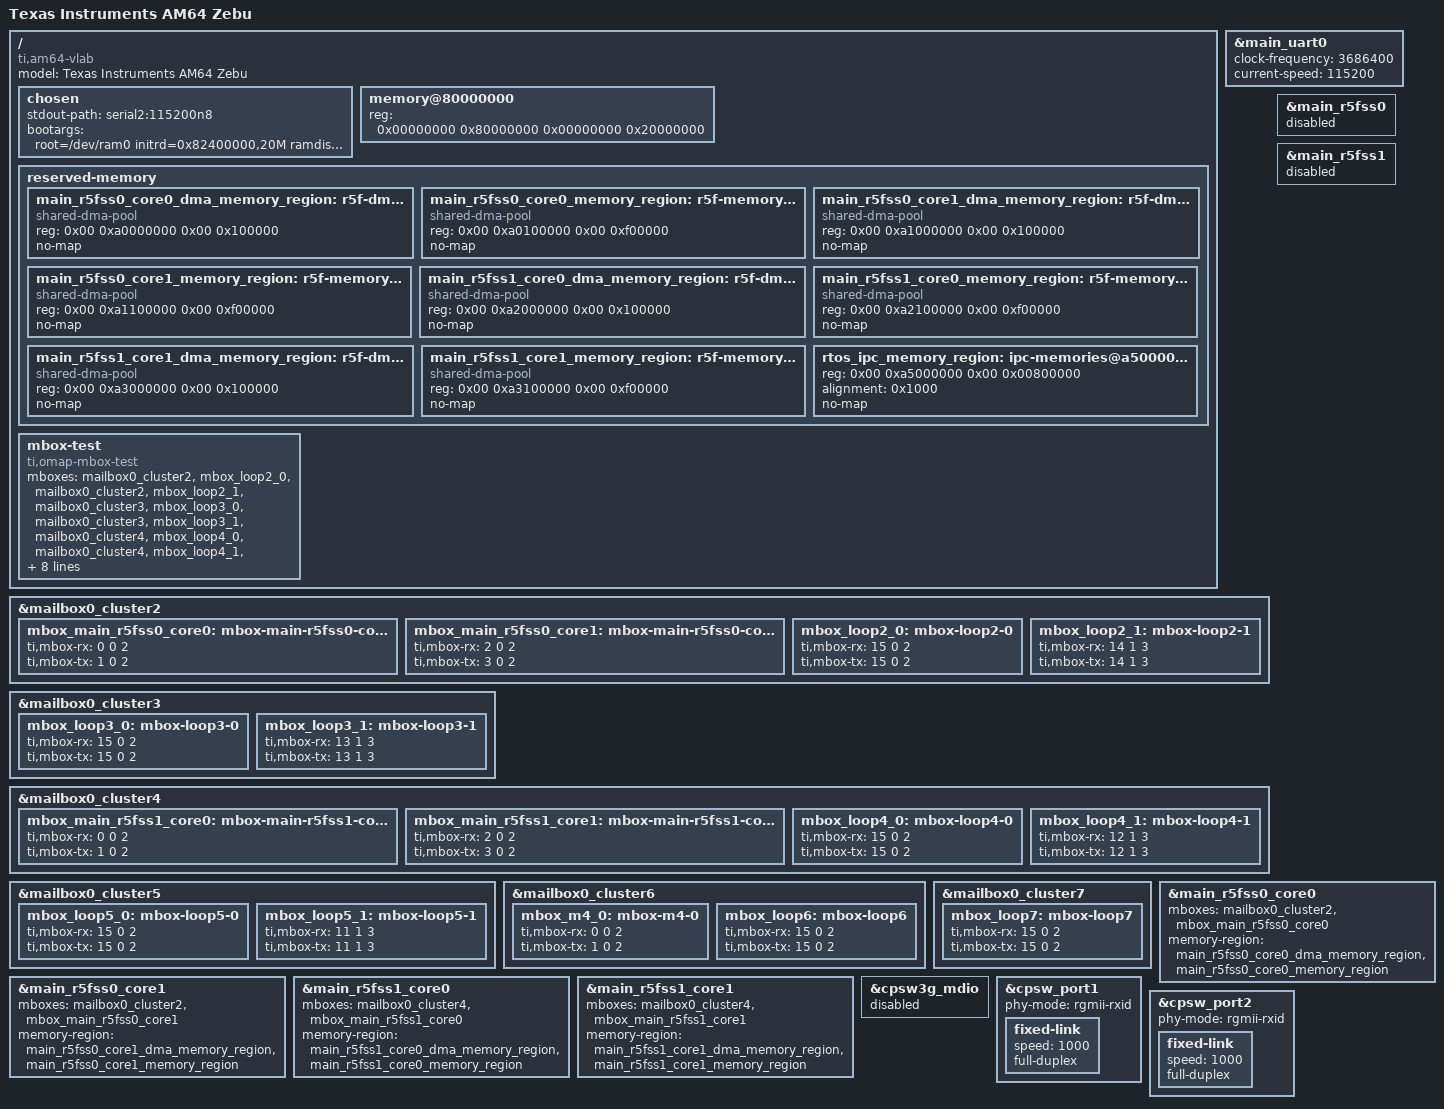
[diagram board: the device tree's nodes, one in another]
// SPDX-License-Identifier: GPL-2.0
/*
 * Copyright (C) 2020 Texas Instruments Incorporated - http://www.ti.com/
 */

/dts-v1/;

#include "k3-am642.dtsi"

/ {
	compatible =  "ti,am64-vlab", "ti,am64";
	model = "Texas Instruments AM64 Zebu";

	chosen {
		stdout-path = "serial2:115200n8";
		bootargs = "root=/dev/ram0 initrd=0x82400000,20M ramdisk_size=20480 init=/bin/sh console=ttyS2,115200n8 earlycon=ns16550a,mmio32,0x02800000";
	};

	memory@80000000 {
		device_type = "memory";
		/* 512MB RAM */
		reg = <0x00000000 0x80000000 0x00000000 0x20000000>;

	};

	reserved-memory {
		#address-cells = <2>;
		#size-cells = <2>;
		ranges;

		main_r5fss0_core0_dma_memory_region: r5f-dma-memory@a0000000 {
			compatible = "shared-dma-pool";
			reg = <0x00 0xa0000000 0x00 0x100000>;
			no-map;
		};

		main_r5fss0_core0_memory_region: r5f-memory@a0100000 {
			compatible = "shared-dma-pool";
			reg = <0x00 0xa0100000 0x00 0xf00000>;
			no-map;
		};

		main_r5fss0_core1_dma_memory_region: r5f-dma-memory@a1000000 {
			compatible = "shared-dma-pool";
			reg = <0x00 0xa1000000 0x00 0x100000>;
			no-map;
		};

		main_r5fss0_core1_memory_region: r5f-memory@a1100000 {
			compatible = "shared-dma-pool";
			reg = <0x00 0xa1100000 0x00 0xf00000>;
			no-map;
		};

		main_r5fss1_core0_dma_memory_region: r5f-dma-memory@a2000000 {
			compatible = "shared-dma-pool";
			reg = <0x00 0xa2000000 0x00 0x100000>;
			no-map;
		};

		main_r5fss1_core0_memory_region: r5f-memory@a2100000 {
			compatible = "shared-dma-pool";
			reg = <0x00 0xa2100000 0x00 0xf00000>;
			no-map;
		};

		main_r5fss1_core1_dma_memory_region: r5f-dma-memory@a3000000 {
			compatible = "shared-dma-pool";
			reg = <0x00 0xa3000000 0x00 0x100000>;
			no-map;
		};

		main_r5fss1_core1_memory_region: r5f-memory@a3100000 {
			compatible = "shared-dma-pool";
			reg = <0x00 0xa3100000 0x00 0xf00000>;
			no-map;
		};

		rtos_ipc_memory_region: ipc-memories@a5000000 {
			reg = <0x00 0xa5000000 0x00 0x00800000>;
			alignment = <0x1000>;
			no-map;
		};
	};

	mbox-test {
		compatible = "ti,omap-mbox-test";
		mboxes = <&mailbox0_cluster2 &mbox_loop2_0>,
			 <&mailbox0_cluster2 &mbox_loop2_1>,
			 <&mailbox0_cluster3 &mbox_loop3_0>,
			 <&mailbox0_cluster3 &mbox_loop3_1>,
			 <&mailbox0_cluster4 &mbox_loop4_0>,
			 <&mailbox0_cluster4 &mbox_loop4_1>,
			 <&mailbox0_cluster5 &mbox_loop5_0>,
			 <&mailbox0_cluster5 &mbox_loop5_1>,
			 <&mailbox0_cluster6 &mbox_loop6>,
			 <&mailbox0_cluster7 &mbox_loop7>;
		mbox-names = "mbox-loop2-0", "mbox-loop2-1",
			     "mbox-loop3-0", "mbox-loop3-1",
			     "mbox-loop4-0", "mbox-loop4-1",
			     "mbox-loop5-0", "mbox-loop5-1",
			     "mbox-loop6", "mbox-loop7";
	};
};
&main_uart0 {
	clock-frequency = <3686400>;
	current-speed = <115200>;
};

&mailbox0_cluster2 {
	mbox_main_r5fss0_core0: mbox-main-r5fss0-core0 {
		ti,mbox-rx = <0 0 2>;
		ti,mbox-tx = <1 0 2>;
	};

	mbox_main_r5fss0_core1: mbox-main-r5fss0-core1 {
		ti,mbox-rx = <2 0 2>;
		ti,mbox-tx = <3 0 2>;
	};

	mbox_loop2_0: mbox-loop2-0 {
		ti,mbox-rx = <15 0 2>;
		ti,mbox-tx = <15 0 2>;
	};

	mbox_loop2_1: mbox-loop2-1 {
		ti,mbox-rx = <14 1 3>;
		ti,mbox-tx = <14 1 3>;
	};
};

&mailbox0_cluster3 {
	mbox_loop3_0: mbox-loop3-0 {
		ti,mbox-rx = <15 0 2>;
		ti,mbox-tx = <15 0 2>;
	};

	mbox_loop3_1: mbox-loop3-1 {
		ti,mbox-rx = <13 1 3>;
		ti,mbox-tx = <13 1 3>;
	};
};

&mailbox0_cluster4 {
	mbox_main_r5fss1_core0: mbox-main-r5fss1-core0 {
		ti,mbox-rx = <0 0 2>;
		ti,mbox-tx = <1 0 2>;
	};

	mbox_main_r5fss1_core1: mbox-main-r5fss1-core1 {
		ti,mbox-rx = <2 0 2>;
		ti,mbox-tx = <3 0 2>;
	};

	mbox_loop4_0: mbox-loop4-0 {
		ti,mbox-rx = <15 0 2>;
		ti,mbox-tx = <15 0 2>;
	};

	mbox_loop4_1: mbox-loop4-1 {
		ti,mbox-rx = <12 1 3>;
		ti,mbox-tx = <12 1 3>;
	};
};

&mailbox0_cluster5 {
	mbox_loop5_0: mbox-loop5-0 {
		ti,mbox-rx = <15 0 2>;
		ti,mbox-tx = <15 0 2>;
	};

	mbox_loop5_1: mbox-loop5-1 {
		ti,mbox-rx = <11 1 3>;
		ti,mbox-tx = <11 1 3>;
	};
};

&mailbox0_cluster6 {
	mbox_m4_0: mbox-m4-0 {
		ti,mbox-rx = <0 0 2>;
		ti,mbox-tx = <1 0 2>;
	};

	mbox_loop6: mbox-loop6 {
		ti,mbox-rx = <15 0 2>;
		ti,mbox-tx = <15 0 2>;
	};
};

&mailbox0_cluster7 {
	mbox_loop7: mbox-loop7 {
		ti,mbox-rx = <15 0 2>;
		ti,mbox-tx = <15 0 2>;
	};
};

&main_r5fss0 {
	status = "disabled";
};

&main_r5fss1 {
	status = "disabled";
};

&main_r5fss0_core0 {
	mboxes = <&mailbox0_cluster2 &mbox_main_r5fss0_core0>;
	memory-region = <&main_r5fss0_core0_dma_memory_region>,
			<&main_r5fss0_core0_memory_region>;
};

&main_r5fss0_core1 {
	mboxes = <&mailbox0_cluster2 &mbox_main_r5fss0_core1>;
	memory-region = <&main_r5fss0_core1_dma_memory_region>,
			<&main_r5fss0_core1_memory_region>;
};

&main_r5fss1_core0 {
	mboxes = <&mailbox0_cluster4 &mbox_main_r5fss1_core0>;
	memory-region = <&main_r5fss1_core0_dma_memory_region>,
			<&main_r5fss1_core0_memory_region>;
};

&main_r5fss1_core1 {
	mboxes = <&mailbox0_cluster4 &mbox_main_r5fss1_core1>;
	memory-region = <&main_r5fss1_core1_dma_memory_region>,
			<&main_r5fss1_core1_memory_region>;
};

&cpsw3g_mdio {
	status = "disabled";
};

&cpsw_port1 {
	phy-mode = "rgmii-rxid";
	fixed-link {
		speed = <1000>;
		full-duplex;
	};
};

&cpsw_port2 {
	phy-mode = "rgmii-rxid";
	fixed-link {
		speed = <1000>;
		full-duplex;
	};
};
